# LM3S815 register map
File version: 7944
Registers are 32-bit, read-write, no defined reset value unless marked. A register's access mark holds for its fields unless they carry their own. Offsets are from the block's base; [hi:lo] are bit positions; {n}, {i} and the like mark numbered series.

## SYSCTL — Register map for SYSCTL peripheral
Base 0x400FE000; register names take the prefix SYSCTL
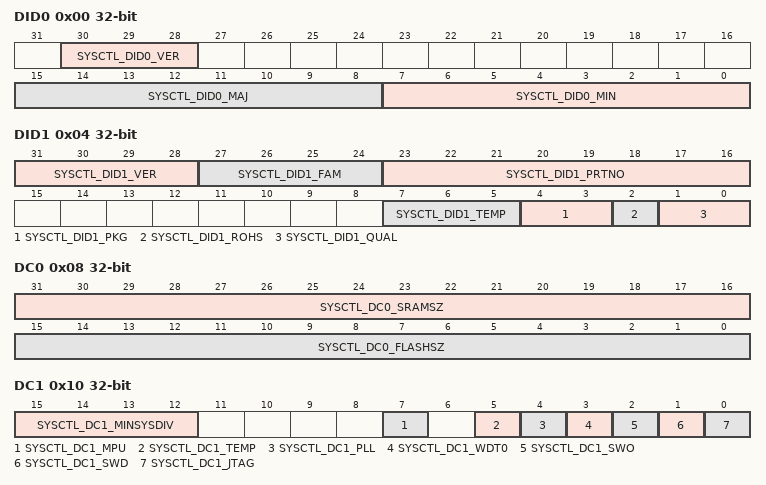
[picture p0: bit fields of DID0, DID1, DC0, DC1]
0x00 DID0 — Device Identification 0
  [30:28] SYSCTL_DID0_VER — DID0 Version
    0=Initial DID0 register format definition for Stellaris(R) Sandstorm-class devices
  [15:8] SYSCTL_DID0_MAJ — Major Revision
    0=SYSCTL_DID0_MAJ_REVA (Revision A (initial device)); 1=SYSCTL_DID0_MAJ_REVB (Revision B (first base layer revision)); 2=SYSCTL_DID0_MAJ_REVC (Revision C (second base layer revision))
  [7:0] SYSCTL_DID0_MIN — Minor Revision
    0=Initial device, or a major revision update; 1=First metal layer change; 2=Second metal layer change
0x04 DID1 — Device Identification 1
  [31:28] SYSCTL_DID1_VER — DID1 Version
    0=Initial DID1 register format definition, indicating a Stellaris LM3Snnn device
  [27:24] SYSCTL_DID1_FAM — Family
    0=SYSCTL_DID1_FAM_STELLARIS (Stellaris family of microcontollers, that is, all devices with external part numbers starting with LM3S)
  [23:16] SYSCTL_DID1_PRTNO — Part Number
    52=LM3S815
  [7:5] SYSCTL_DID1_TEMP — Temperature Range
    0=SYSCTL_DID1_TEMP_C (Commercial temperature range (0C to 70C)); 1=SYSCTL_DID1_TEMP_I (Industrial temperature range (-40C to 85C)); 2=SYSCTL_DID1_TEMP_E (Extended temperature range (-40C to 105C))
  [4:3] SYSCTL_DID1_PKG — Package Type
    0=SYSCTL_DID1_PKG_SOIC (SOIC package); 1=SYSCTL_DID1_PKG_QFP (LQFP package); 3=SYSCTL_DID1_PKG_QFN (QFN package)
  [2] SYSCTL_DID1_ROHS — RoHS-Compliance
  [1:0] SYSCTL_DID1_QUAL — Qualification Status
    0=SYSCTL_DID1_QUAL_ES (Engineering Sample (unqualified)); 1=SYSCTL_DID1_QUAL_PP (Pilot Production (unqualified)); 2=SYSCTL_DID1_QUAL_FQ (Fully Qualified)
0x08 DC0 — Device Capabilities 0
  [31:16] SYSCTL_DC0_SRAMSZ — SRAM Size
    31=SYSCTL_DC0_SRAMSZ_8KB (8 KB of SRAM)
  [15:0] SYSCTL_DC0_FLASHSZ — Flash Size
    31=SYSCTL_DC0_FLASHSZ_64KB (64 KB of Flash)
0x10 DC1 — Device Capabilities 1
  [15:12] SYSCTL_DC1_MINSYSDIV — System Clock Divider
    3=Specifies a 50-MHz CPU clock with a PLL divider of 4
  [7] SYSCTL_DC1_MPU — MPU Present
  [5] SYSCTL_DC1_TEMP — Temp Sensor Present
  [4] SYSCTL_DC1_PLL — PLL Present
  [3] SYSCTL_DC1_WDT0 — Watchdog Timer 0 Present
  [2] SYSCTL_DC1_SWO — SWO Trace Port Present
  [1] SYSCTL_DC1_SWD — SWD Present
  [0] SYSCTL_DC1_JTAG — JTAG Present
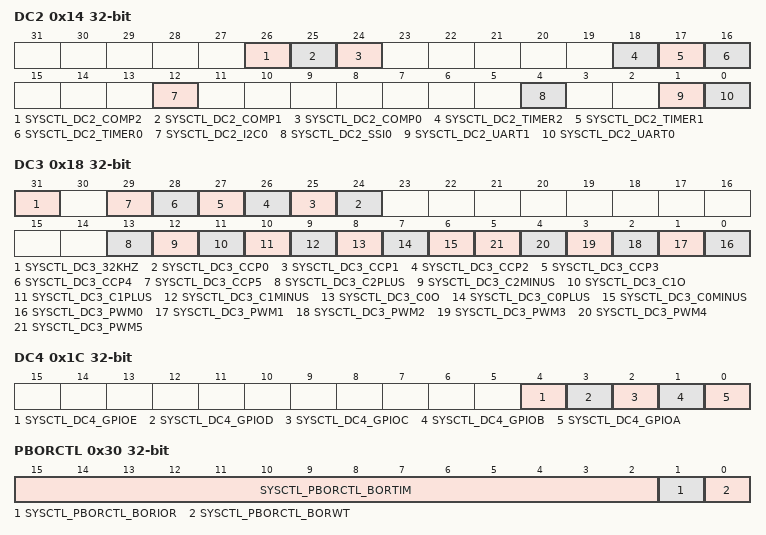
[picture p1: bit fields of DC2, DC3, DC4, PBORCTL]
0x14 DC2 — Device Capabilities 2
  [26] SYSCTL_DC2_COMP2 — Analog Comparator 2 Present
  [25] SYSCTL_DC2_COMP1 — Analog Comparator 1 Present
  [24] SYSCTL_DC2_COMP0 — Analog Comparator 0 Present
  [18] SYSCTL_DC2_TIMER2 — Timer Module 2 Present
  [17] SYSCTL_DC2_TIMER1 — Timer Module 1 Present
  [16] SYSCTL_DC2_TIMER0 — Timer Module 0 Present
  [12] SYSCTL_DC2_I2C0 — I2C Module 0 Present
  [4] SYSCTL_DC2_SSI0 — SSI Module 0 Present
  [1] SYSCTL_DC2_UART1 — UART Module 1 Present
  [0] SYSCTL_DC2_UART0 — UART Module 0 Present
0x18 DC3 — Device Capabilities 3
  [31] SYSCTL_DC3_32KHZ — 32KHz Input Clock Available
  [n+24] SYSCTL_DC3_CCP{n} (n=0..5) — CCP{n} Pin Present
  [13] SYSCTL_DC3_C2PLUS — C2+ Pin Present
  [12] SYSCTL_DC3_C2MINUS — C2- Pin Present
  [11] SYSCTL_DC3_C1O — C1o Pin Present
  [10] SYSCTL_DC3_C1PLUS — C1+ Pin Present
  [9] SYSCTL_DC3_C1MINUS — C1- Pin Present
  [8] SYSCTL_DC3_C0O — C0o Pin Present
  [7] SYSCTL_DC3_C0PLUS — C0+ Pin Present
  [6] SYSCTL_DC3_C0MINUS — C0- Pin Present
  [n] SYSCTL_DC3_PWM{n} (n=0..5) — PWM{n} Pin Present
0x1C DC4 — Device Capabilities 4
  [4] SYSCTL_DC4_GPIOE — GPIO Port E Present
  [3] SYSCTL_DC4_GPIOD — GPIO Port D Present
  [2] SYSCTL_DC4_GPIOC — GPIO Port C Present
  [1] SYSCTL_DC4_GPIOB — GPIO Port B Present
  [0] SYSCTL_DC4_GPIOA — GPIO Port A Present
0x30 PBORCTL — Brown-Out Reset Control
  [15:2] SYSCTL_PBORCTL_BORTIM — BOR Time Delay
  [1] SYSCTL_PBORCTL_BORIOR — BOR Interrupt or Reset
  [0] SYSCTL_PBORCTL_BORWT — BOR Wait and Check for Noise
0x34 LDOPCTL — LDO Power Control
  [5:0] SYSCTL_LDOPCTL — LDO Output Voltage
    0=SYSCTL_LDOPCTL_2_50V (2.50); 1=SYSCTL_LDOPCTL_2_45V (2.45); 2=SYSCTL_LDOPCTL_2_40V (2.40); 3=SYSCTL_LDOPCTL_2_35V (2.35); 4=SYSCTL_LDOPCTL_2_30V (2.30); 5=SYSCTL_LDOPCTL_2_25V (2.25); 27=SYSCTL_LDOPCTL_2_75V (2.75); 28=SYSCTL_LDOPCTL_2_70V (2.70); 29=SYSCTL_LDOPCTL_2_65V (2.65); 30=SYSCTL_LDOPCTL_2_60V (2.60); 31=SYSCTL_LDOPCTL_2_55V (2.55)
0x40 SRCR0 — Software Reset Control 0
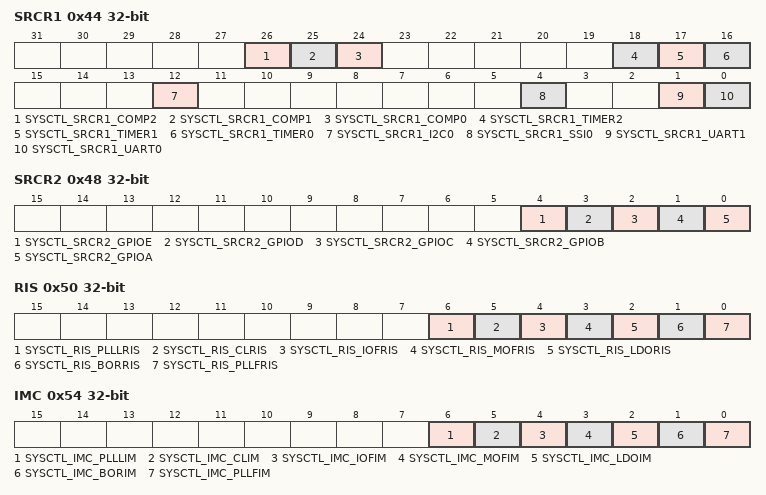
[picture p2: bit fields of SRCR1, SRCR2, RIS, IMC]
0x44 SRCR1 — Software Reset Control 1
  [26] SYSCTL_SRCR1_COMP2 — Analog Comp 2 Reset Control
  [25] SYSCTL_SRCR1_COMP1 — Analog Comp 1 Reset Control
  [24] SYSCTL_SRCR1_COMP0 — Analog Comp 0 Reset Control
  [18] SYSCTL_SRCR1_TIMER2 — Timer 2 Reset Control
  [17] SYSCTL_SRCR1_TIMER1 — Timer 1 Reset Control
  [16] SYSCTL_SRCR1_TIMER0 — Timer 0 Reset Control
  [12] SYSCTL_SRCR1_I2C0 — I2C0 Reset Control
  [4] SYSCTL_SRCR1_SSI0 — SSI0 Reset Control
  [1] SYSCTL_SRCR1_UART1 — UART1 Reset Control
  [0] SYSCTL_SRCR1_UART0 — UART0 Reset Control
0x48 SRCR2 — Software Reset Control 2
  [4] SYSCTL_SRCR2_GPIOE — Port E Reset Control
  [3] SYSCTL_SRCR2_GPIOD — Port D Reset Control
  [2] SYSCTL_SRCR2_GPIOC — Port C Reset Control
  [1] SYSCTL_SRCR2_GPIOB — Port B Reset Control
  [0] SYSCTL_SRCR2_GPIOA — Port A Reset Control
0x50 RIS — Raw Interrupt Status
  [6] SYSCTL_RIS_PLLLRIS — PLL Lock Raw Interrupt Status
  [5] SYSCTL_RIS_CLRIS — Current Limit Raw Interrupt Status
  [4] SYSCTL_RIS_IOFRIS — Internal Oscillator Fault Raw Interrupt Status
  [3] SYSCTL_RIS_MOFRIS — Main Oscillator Fault Raw Interrupt Status
  [2] SYSCTL_RIS_LDORIS — LDO Power Unregulated Raw Interrupt Status
  [1] SYSCTL_RIS_BORRIS — Brown-Out Reset Raw Interrupt Status
  [0] SYSCTL_RIS_PLLFRIS — PLL Fault Raw Interrupt Status
0x54 IMC — Interrupt Mask Control
  [6] SYSCTL_IMC_PLLLIM — PLL Lock Interrupt Mask
  [5] SYSCTL_IMC_CLIM — Current Limit Interrupt Mask
  [4] SYSCTL_IMC_IOFIM — Internal Oscillator Fault Interrupt Mask
  [3] SYSCTL_IMC_MOFIM — Main Oscillator Fault Interrupt Mask
  [2] SYSCTL_IMC_LDOIM — LDO Power Unregulated Interrupt Mask
  [1] SYSCTL_IMC_BORIM — Brown-Out Reset Interrupt Mask
  [0] SYSCTL_IMC_PLLFIM — PLL Fault Interrupt Mask
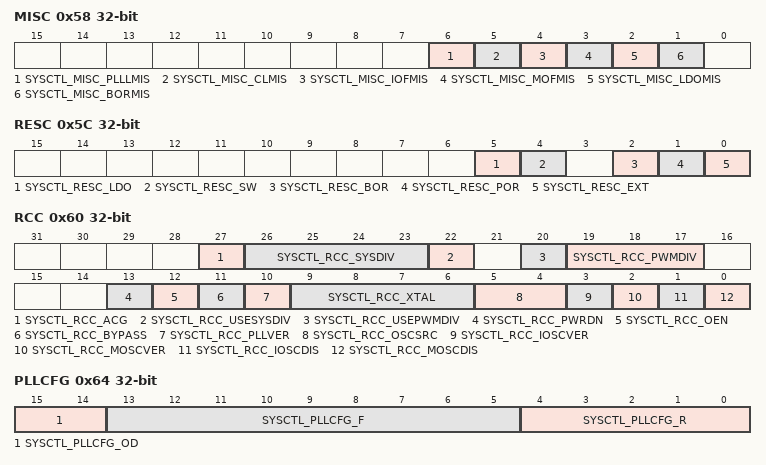
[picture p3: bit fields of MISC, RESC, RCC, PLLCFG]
0x58 MISC — Masked Interrupt Status and Clear
  [6] SYSCTL_MISC_PLLLMIS — PLL Lock Masked Interrupt Status
  [5] SYSCTL_MISC_CLMIS — Current Limit Masked Interrupt Status
  [4] SYSCTL_MISC_IOFMIS — Internal Oscillator Fault Masked Interrupt Status
  [3] SYSCTL_MISC_MOFMIS — Main Oscillator Fault Masked Interrupt Status
  [2] SYSCTL_MISC_LDOMIS — LDO Power Unregulated Masked Interrupt Status
  [1] SYSCTL_MISC_BORMIS — BOR Masked Interrupt Status
0x5C RESC — Reset Cause
  [5] SYSCTL_RESC_LDO — LDO Reset
  [4] SYSCTL_RESC_SW — Software Reset
  [2] SYSCTL_RESC_BOR — Brown-Out Reset
  [1] SYSCTL_RESC_POR — Power-On Reset
  [0] SYSCTL_RESC_EXT — External Reset
0x60 RCC — Run-Mode Clock Configuration
  [27] SYSCTL_RCC_ACG — Auto Clock Gating
  [26:23] SYSCTL_RCC_SYSDIV — System Clock Divisor
    {v}=System clock /{v+1} (v=1..15)
  [22] SYSCTL_RCC_USESYSDIV — Enable System Clock Divider
  [20] SYSCTL_RCC_USEPWMDIV — Enable PWM Clock Divisor
  [19:17] SYSCTL_RCC_PWMDIV — PWM Unit Clock Divisor
    0=PWM clock /2; 1=PWM clock /4; 2=PWM clock /8; 3=PWM clock /16; 4=PWM clock /32; 5=PWM clock /64
  [13] SYSCTL_RCC_PWRDN — PLL Power Down
  [12] SYSCTL_RCC_OEN — PLL Output Enable
  [11] SYSCTL_RCC_BYPASS — PLL Bypass
  [10] SYSCTL_RCC_PLLVER — PLL Verification
  [9:6] SYSCTL_RCC_XTAL — Crystal Value
    0=SYSCTL_RCC_XTAL_1MHZ (1 MHz); 1=SYSCTL_RCC_XTAL_1_84MHZ (1.8432 MHz); 2=SYSCTL_RCC_XTAL_2MHZ (2 MHz); 3=SYSCTL_RCC_XTAL_2_45MHZ (2.4576 MHz); 4=SYSCTL_RCC_XTAL_3_57MHZ (3.579545 MHz); 5=SYSCTL_RCC_XTAL_3_68MHZ (3.6864 MHz); 6=SYSCTL_RCC_XTAL_4MHZ (4 MHz); 7=SYSCTL_RCC_XTAL_4_09MHZ (4.096 MHz); 8=SYSCTL_RCC_XTAL_4_91MHZ (4.9152 MHz); 9=SYSCTL_RCC_XTAL_5MHZ (5 MHz); 10=SYSCTL_RCC_XTAL_5_12MHZ (5.12 MHz); 11=SYSCTL_RCC_XTAL_6MHZ (6 MHz); 12=SYSCTL_RCC_XTAL_6_14MHZ (6.144 MHz); 13=SYSCTL_RCC_XTAL_7_37MHZ (7.3728 MHz); 14=SYSCTL_RCC_XTAL_8MHZ (8 MHz); 15=SYSCTL_RCC_XTAL_8_19MHZ (8.192 MHz)
  [5:4] SYSCTL_RCC_OSCSRC — Oscillator Source
    0=SYSCTL_RCC_OSCSRC_MAIN (MOSC); 1=SYSCTL_RCC_OSCSRC_INT (IOSC); 2=SYSCTL_RCC_OSCSRC_INT4 (IOSC/4)
  [3] SYSCTL_RCC_IOSCVER — Internal Oscillator Verification Timer
  [2] SYSCTL_RCC_MOSCVER — Main Oscillator Verification Timer
  [1] SYSCTL_RCC_IOSCDIS — Internal Oscillator Disable
  [0] SYSCTL_RCC_MOSCDIS — Main Oscillator Disable
0x64 PLLCFG — XTAL to PLL Translation
  [15:14] SYSCTL_PLLCFG_OD — PLL OD Value
    0=Divide by 1; 1=Divide by 2; 2=Divide by 4
  [13:5] SYSCTL_PLLCFG_F — PLL F Value
  [4:0] SYSCTL_PLLCFG_R — PLL R Value
0x100 RCGC0 — Run Mode Clock Gating Control Register 0
  [9:8] SYSCTL_RCGC0_ADCSPD — ADC Sample Speed
    0=SYSCTL_RCGC0_ADCSPD125K (125K samples/second); 1=SYSCTL_RCGC0_ADCSPD250K (250K samples/second); 2=SYSCTL_RCGC0_ADCSPD500K (500K samples/second)
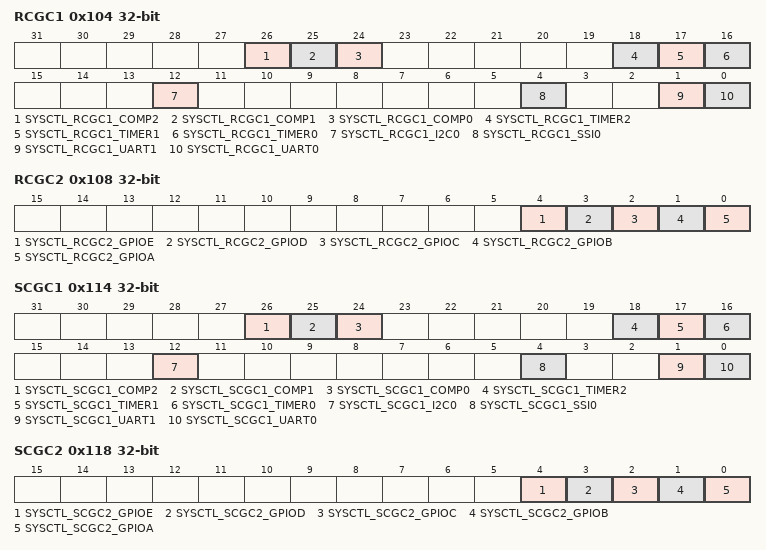
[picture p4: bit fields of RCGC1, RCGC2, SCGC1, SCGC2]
0x104 RCGC1 — Run Mode Clock Gating Control Register 1
  [26] SYSCTL_RCGC1_COMP2 — Analog Comparator 2 Clock Gating
  [25] SYSCTL_RCGC1_COMP1 — Analog Comparator 1 Clock Gating
  [24] SYSCTL_RCGC1_COMP0 — Analog Comparator 0 Clock Gating
  [18] SYSCTL_RCGC1_TIMER2 — Timer 2 Clock Gating Control
  [17] SYSCTL_RCGC1_TIMER1 — Timer 1 Clock Gating Control
  [16] SYSCTL_RCGC1_TIMER0 — Timer 0 Clock Gating Control
  [12] SYSCTL_RCGC1_I2C0 — I2C0 Clock Gating Control
  [4] SYSCTL_RCGC1_SSI0 — SSI0 Clock Gating Control
  [1] SYSCTL_RCGC1_UART1 — UART1 Clock Gating Control
  [0] SYSCTL_RCGC1_UART0 — UART0 Clock Gating Control
0x108 RCGC2 — Run Mode Clock Gating Control Register 2
  [4] SYSCTL_RCGC2_GPIOE — Port E Clock Gating Control
  [3] SYSCTL_RCGC2_GPIOD — Port D Clock Gating Control
  [2] SYSCTL_RCGC2_GPIOC — Port C Clock Gating Control
  [1] SYSCTL_RCGC2_GPIOB — Port B Clock Gating Control
  [0] SYSCTL_RCGC2_GPIOA — Port A Clock Gating Control
0x110 SCGC0 — Sleep Mode Clock Gating Control Register 0
  [9:8] SYSCTL_SCGC0_ADCSPD — ADC Sample Speed
    0=SYSCTL_SCGC0_ADCSPD125K (125K samples/second); 1=SYSCTL_SCGC0_ADCSPD250K (250K samples/second); 2=SYSCTL_SCGC0_ADCSPD500K (500K samples/second)
0x114 SCGC1 — Sleep Mode Clock Gating Control Register 1
  [26] SYSCTL_SCGC1_COMP2 — Analog Comparator 2 Clock Gating
  [25] SYSCTL_SCGC1_COMP1 — Analog Comparator 1 Clock Gating
  [24] SYSCTL_SCGC1_COMP0 — Analog Comparator 0 Clock Gating
  [18] SYSCTL_SCGC1_TIMER2 — Timer 2 Clock Gating Control
  [17] SYSCTL_SCGC1_TIMER1 — Timer 1 Clock Gating Control
  [16] SYSCTL_SCGC1_TIMER0 — Timer 0 Clock Gating Control
  [12] SYSCTL_SCGC1_I2C0 — I2C0 Clock Gating Control
  [4] SYSCTL_SCGC1_SSI0 — SSI0 Clock Gating Control
  [1] SYSCTL_SCGC1_UART1 — UART1 Clock Gating Control
  [0] SYSCTL_SCGC1_UART0 — UART0 Clock Gating Control
0x118 SCGC2 — Sleep Mode Clock Gating Control Register 2
  [4] SYSCTL_SCGC2_GPIOE — Port E Clock Gating Control
  [3] SYSCTL_SCGC2_GPIOD — Port D Clock Gating Control
  [2] SYSCTL_SCGC2_GPIOC — Port C Clock Gating Control
  [1] SYSCTL_SCGC2_GPIOB — Port B Clock Gating Control
  [0] SYSCTL_SCGC2_GPIOA — Port A Clock Gating Control
0x120 DCGC0 — Deep Sleep Mode Clock Gating Control Register 0
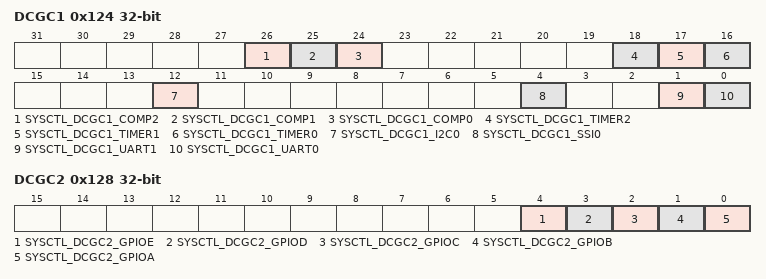
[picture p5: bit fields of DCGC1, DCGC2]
0x124 DCGC1 — Deep-Sleep Mode Clock Gating Control Register 1
  [26] SYSCTL_DCGC1_COMP2 — Analog Comparator 2 Clock Gating
  [25] SYSCTL_DCGC1_COMP1 — Analog Comparator 1 Clock Gating
  [24] SYSCTL_DCGC1_COMP0 — Analog Comparator 0 Clock Gating
  [18] SYSCTL_DCGC1_TIMER2 — Timer 2 Clock Gating Control
  [17] SYSCTL_DCGC1_TIMER1 — Timer 1 Clock Gating Control
  [16] SYSCTL_DCGC1_TIMER0 — Timer 0 Clock Gating Control
  [12] SYSCTL_DCGC1_I2C0 — I2C0 Clock Gating Control
  [4] SYSCTL_DCGC1_SSI0 — SSI0 Clock Gating Control
  [1] SYSCTL_DCGC1_UART1 — UART1 Clock Gating Control
  [0] SYSCTL_DCGC1_UART0 — UART0 Clock Gating Control
0x128 DCGC2 — Deep Sleep Mode Clock Gating Control Register 2
  [4] SYSCTL_DCGC2_GPIOE — Port E Clock Gating Control
  [3] SYSCTL_DCGC2_GPIOD — Port D Clock Gating Control
  [2] SYSCTL_DCGC2_GPIOC — Port C Clock Gating Control
  [1] SYSCTL_DCGC2_GPIOB — Port B Clock Gating Control
  [0] SYSCTL_DCGC2_GPIOA — Port A Clock Gating Control
0x144 DSLPCLKCFG — Deep Sleep Clock Configuration
  [0] SYSCTL_DSLPCLKCFG_IOSC — IOSC Clock Source
0x150 CLKVCLR — Clock Verification Clear
  [0] SYSCTL_CLKVCLR_VERCLR
0x160 LDOARST — Allow Unregulated LDO to Reset the Part
  [0] SYSCTL_LDOARST_LDOARST — LDO Reset
